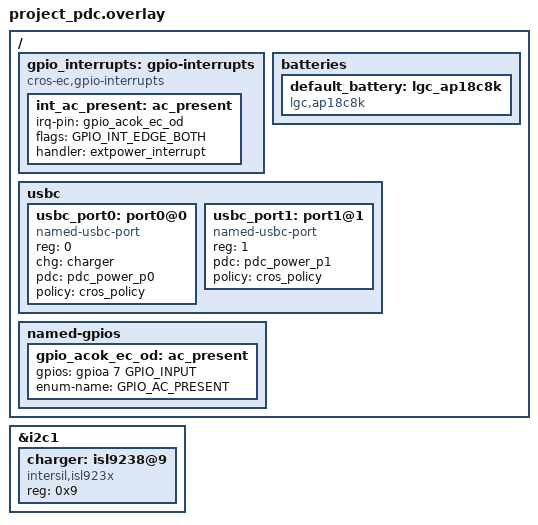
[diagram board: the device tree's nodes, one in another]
/* Copyright 2025 The ChromiumOS Authors
 * Use of this source code is governed by a BSD-style license that can be
 * found in the LICENSE file.
 */

#include <usbc-policy.dtsi>

/{
	gpio_interrupts: gpio-interrupts {
		compatible = "cros-ec,gpio-interrupts";

		int_ac_present: ac_present {
			irq-pin = <&gpio_acok_ec_od>;
			flags = <GPIO_INT_EDGE_BOTH>;
			handler = "extpower_interrupt";
		};
	};

	batteries {
                default_battery: lgc_ap18c8k {
                        compatible = "lgc,ap18c8k", "battery-smart";
                };
        };

	usbc {
		#address-cells = <1>;
		#size-cells = <0>;
		usbc_port0: port0@0 {
			compatible = "named-usbc-port";
			reg = <0>;
			chg = <&charger>;
			pdc = <&pdc_power_p0>;
			policy = <&cros_policy>;
		};
		usbc_port1: port1@1 {
			compatible = "named-usbc-port";
			reg = <1>;
			pdc = <&pdc_power_p1>;
			policy = <&cros_policy>;
		};
	};

	named-gpios {
		gpio_acok_ec_od: ac_present {
			/* AC_IN_SW/STD_ADPT_CNTL_GPIO_R */
			gpios = <&gpioa 7 GPIO_INPUT>;
			enum-name = "GPIO_AC_PRESENT";
		};
	};
};

&i2c1 {
	charger: isl9238@9 {
		compatible = "intersil,isl923x";
		status = "okay";
		reg = <0x9>;
	};
};
